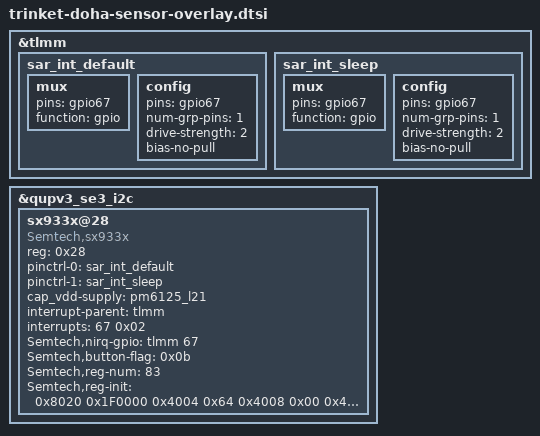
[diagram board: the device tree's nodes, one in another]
/* Copyright (c) 2018, The Linux Foundation. All rights reserved.
 *
 * This program is free software; you can redistribute it and/or modify
 * it under the terms of the GNU General Public License version 2 and
 * only version 2 as published by the Free Software Foundation.
 *
 * This program is distributed in the hope that it will be useful,
 * but WITHOUT ANY WARRANTY; without even the implied warranty of
 * MERCHANTABILITY or FITNESS FOR A PARTICULAR PURPOSE.  See the
 * GNU General Public License for more details.
 */

&tlmm {
	sar_int_default: sar_int_default {
			mux {
				pins = "gpio67";
				function =  "gpio";
			};
			config {
				pins = "gpio67";
				num-grp-pins = <1>;
				drive-strength = <2>;
				bias-no-pull;
			};
	};

	sar_int_sleep: sar_int_sleep {
			mux {
				pins = "gpio67";
				function =  "gpio";
			};
			config {
				pins = "gpio67";
				num-grp-pins = <1>;
				drive-strength = <2>;
				bias-no-pull;
			};
	};
};


&qupv3_se3_i2c {
	status = "ok";
	sx933x@28 { /* SAR sensor */
		compatible = "Semtech,sx933x";
		reg = <0x28>;
		pinctrl-names = "default","sleep";
		pinctrl-0 = <&sar_int_default>;
		pinctrl-1 = <&sar_int_sleep>;
		cap_vdd-supply = <&pm6125_l21>;
		interrupt-parent = <&tlmm>;
		interrupts = <67 0x02>;
		interrupt-names = "sx933x_irq";
		Semtech,nirq-gpio= <&tlmm 67 0x02>;
		Semtech,button-flag = <0x0b>;
		Semtech,reg-num = <83>;
		Semtech,reg-init =<
		0x8020 0x1F0000
		0x4004 0x64
		0x4008 0x00
		0x4054 0x400
		0x42C0 0x8000000
		0x42C4 0x3F
		0x800C 0x00
		0x8010 0x00
		0x8014 0x00
		0x8018 0x00
		0x801C 0x58
		0x8024 0x300014BE
		0x8028 0x3FFE82C2
		0x802C 0x300014BE
		0x8030 0x3FF7825F
		0x8034 0x14BE
		0x8038 0x3FBF82C2
		0x803C 0x1446
		0x8040 0x3DFF8261
		0x8044 0x300014BE
		0x8048 0x2FFF82C7
		0x804C 0x88E
		0x8050 0x80001EE6
		0x8054 0x10163D00
		0x8058 0x60600031
		0x805C 0x54AC5300
		0x8060 0x00
		0x8064 0x810000
		0x8068 0x00
		0x806C 0x21002100
		0x8070 0x10000
		0x8074 0x10162A00
		0x8078 0x60600031
		0x807C 0x54AC5300
		0x8080 0x00
		0x8084 0x460000
		0x8088 0x00
		0x808C 0x1E001E00
		0x8090 0x10000
		0x8094 0x1052C800
		0x8098 0x60600931
		0x809C 0x54AC4300
		0x80A0 0x00
		0x80A4 0x00
		0x80A8 0x00
		0x80AC 0x00
		0x80B0 0x00
		0x80B4 0x10123500
		0x80B8 0x60600031
		0x80BC 0x54AC5300
		0x80C0 0x00
		0x80C4 0x5C0000
		0x80C8 0x00
		0x80CC 0x500050
		0x80D0 0x20000
		0x80D4 0x1052C800
		0x80D8 0x60600931
		0x80DC 0x54AC4300
		0x80E0 0x00
		0x80E4 0x00
		0x80E8 0x00
		0x80EC 0x00
		0x80F0 0x00
		0x80F4 0x10162800
		0x80F8 0x20400031
		0x80FC 0x54AC5300
		0x8100 0x00
		0x8104 0x00
		0x8108 0x00
		0x810C 0x00
		0x8110 0x00
		0x8124 0x4000004
		0x8128 0x4000002
		0x812C 0x00
		0x8130 0x00
		0x8134 0x00
		0x8138 0x00
		0x813C 0x00
		0x8140 0x00
		0x8144 0x00
		0x8148 0x00
		0x814C 0x00
		0x81A4 0x1D40008>;
		status = "ok";
	};
};
